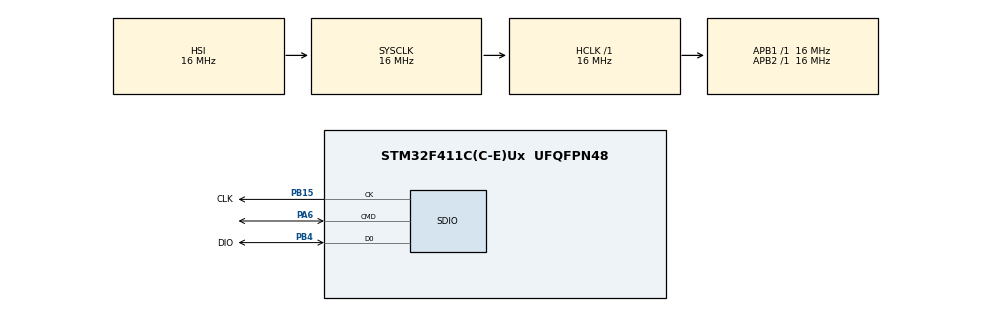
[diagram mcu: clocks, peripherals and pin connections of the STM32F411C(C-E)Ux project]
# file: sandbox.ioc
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Mcu.Family=STM32F4
Mcu.Name=STM32F411C(C-E)Ux
Mcu.Package=UFQFPN48
NVIC.PriorityGroup=NVIC_PRIORITYGROUP_4
PA6.Mode=SD_1_bit
PA6.Signal=SDIO_CMD
PB15.GPIO_Label=CLK
PB15.Mode=SD_1_bit
PB15.Signal=SDIO_CK
PB4.GPIO_Label=DIO
PB4.Mode=SD_1_bit
PB4.Signal=SDIO_D0
ProjectManager.HeapSize=0x200
ProjectManager.StackSize=0x400
ProjectManager.TargetToolchain=STM32CubeIDE
RCC.AHBFreq_Value=16000000
RCC.APB1Freq_Value=16000000
RCC.APB2Freq_Value=16000000
RCC.CortexFreq_Value=16000000
RCC.HSE_VALUE=25000000
RCC.HSI_VALUE=16000000
RCC.LSE_VALUE=32768
RCC.SYSCLKFreq_VALUE=16000000
RCC.VCOOutputFreq_Value=192000000
board=custom

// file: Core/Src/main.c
/* USER CODE BEGIN Header */
/**
  ******************************************************************************
  * @file           : main.c
  * @brief          : Main program body
  ******************************************************************************
  * @attention
  *
  * Copyright (c) 2023 STMicroelectronics.
  * All rights reserved.
  *
  * This software is licensed under terms that can be found in the LICENSE file
  * in the root directory of this software component.
  * If no LICENSE file comes with this software, it is provided AS-IS.
  *
  ******************************************************************************
  */
/* USER CODE END Header */
#include "main.h"
#include <TM1637Display.h>

SD_HandleTypeDef hsd;

void SystemClock_Config(void);
static void MX_GPIO_Init(void);
static void MX_SDIO_SD_Init(void);

int main(void)
{

  /* MCU Configuration--------------------------------------------------------*/

  /* Reset of all peripherals, Initializes the Flash interface and the Systick. */
  HAL_Init();

  /* Configure the system clock */
  SystemClock_Config();

  /* Initialize all configured peripherals */
  MX_GPIO_Init();
  MX_SDIO_SD_Init();
  /* USER CODE BEGIN 2 */
  // Create display object of type TM1637Display:
  TM1637Display display = TM1637Display(CLK_Pin, DIO_Pin);

  // Create array that turns all segments on:
  const uint8_t data[] = {0xff, 0xff, 0xff, 0xff};

  // Create array that turns all segments off:
  const uint8_t blank[] = {0x00, 0x00, 0x00, 0x00};

  // You can set the individual segments per digit to spell words or create other symbols:
  const uint8_t done[] = {
    SEG_B | SEG_C | SEG_D | SEG_E | SEG_G,           // d
    SEG_A | SEG_B | SEG_C | SEG_D | SEG_E | SEG_F,   // O
    SEG_C | SEG_E | SEG_G,                           // n
    SEG_A | SEG_D | SEG_E | SEG_F | SEG_G            // E
  };

  // Create degree Celsius symbol:
  const uint8_t celsius[] = {
    SEG_A | SEG_B | SEG_F | SEG_G,  // Circle
    SEG_A | SEG_D | SEG_E | SEG_F   // C
  };

  void setup() {
    // Clear the display:
    display.clear();
    delay(1000);
  }

  void loop() {
    // Set the brightness:
    display.setBrightness(7);
    // All segments on:
    display.setSegments(data);

    delay(1000);
    display.clear();
    delay(1000);

    // Show counter:
    int i;
    for (i = 0; i < 101; i++) {
      display.showNumberDec(i);
      delay(50);
    }

    delay(1000);
    display.clear();
    delay(1000);

    // Print number in different locations, loops 2 times:
    int j;
    for (j = 0; j < 2; j++) {
      for (i = 0; i < 4; i++) {
        display.showNumberDec(i, false, 1, i);
        delay(500);
        display.clear();
      }
    }

    delay(1000);
    display.clear();
    delay(1000);

    // Set brightness (0-7):
    int k;
    for (k = 0; k < 8; k++) {
      display.setBrightness(k);
      display.setSegments(data);
      delay(500);
    }

    delay(1000);
    display.clear();
    delay(1000);

    // Print 1234 with the center colon:
    display.showNumberDecEx(1234, 0b11100000, false, 4, 0);

    delay(1000);
    display.clear();
    delay(1000);

    int temperature = 24;
    display.showNumberDec(temperature, false, 2, 0);
    display.setSegments(celsius, 2, 2);

    delay(1000);
    display.clear();
    delay(1000);

    display.setSegments(done);
  /* USER CODE END 2 */

  /* Infinite loop */
  while (1)
  {

  }
}

void SystemClock_Config(void)
{
  RCC_OscInitTypeDef RCC_OscInitStruct = {0};
  RCC_ClkInitTypeDef RCC_ClkInitStruct = {0};

  /** Configure the main internal regulator output voltage
  */
  __HAL_RCC_PWR_CLK_ENABLE();
  __HAL_PWR_VOLTAGESCALING_CONFIG(PWR_REGULATOR_VOLTAGE_SCALE1);

  /** Initializes the RCC Oscillators according to the specified parameters
  * in the RCC_OscInitTypeDef structure.
  */
  RCC_OscInitStruct.OscillatorType = RCC_OSCILLATORTYPE_HSI;
  RCC_OscInitStruct.HSIState = RCC_HSI_ON;
  RCC_OscInitStruct.HSICalibrationValue = RCC_HSICALIBRATION_DEFAULT;
  RCC_OscInitStruct.PLL.PLLState = RCC_PLL_ON;
  RCC_OscInitStruct.PLL.PLLSource = RCC_PLLSOURCE_HSI;
  RCC_OscInitStruct.PLL.PLLM = 16;
  RCC_OscInitStruct.PLL.PLLN = 192;
  RCC_OscInitStruct.PLL.PLLP = RCC_PLLP_DIV2;
  RCC_OscInitStruct.PLL.PLLQ = 4;
  if (HAL_RCC_OscConfig(&RCC_OscInitStruct) != HAL_OK)
  {
    Error_Handler();
  }

  /** Initializes the CPU, AHB and APB buses clocks
  */
  RCC_ClkInitStruct.ClockType = RCC_CLOCKTYPE_HCLK|RCC_CLOCKTYPE_SYSCLK
                              |RCC_CLOCKTYPE_PCLK1|RCC_CLOCKTYPE_PCLK2;
  RCC_ClkInitStruct.SYSCLKSource = RCC_SYSCLKSOURCE_HSI;
  RCC_ClkInitStruct.AHBCLKDivider = RCC_SYSCLK_DIV1;
  RCC_ClkInitStruct.APB1CLKDivider = RCC_HCLK_DIV1;
  RCC_ClkInitStruct.APB2CLKDivider = RCC_HCLK_DIV1;

  if (HAL_RCC_ClockConfig(&RCC_ClkInitStruct, FLASH_LATENCY_0) != HAL_OK)
  {
    Error_Handler();
  }
}

static void MX_SDIO_SD_Init(void)
{

  hsd.Instance = SDIO;
  hsd.Init.ClockEdge = SDIO_CLOCK_EDGE_RISING;
  hsd.Init.ClockBypass = SDIO_CLOCK_BYPASS_DISABLE;
  hsd.Init.ClockPowerSave = SDIO_CLOCK_POWER_SAVE_DISABLE;
  hsd.Init.BusWide = SDIO_BUS_WIDE_1B;
  hsd.Init.HardwareFlowControl = SDIO_HARDWARE_FLOW_CONTROL_DISABLE;
  hsd.Init.ClockDiv = 0;
  if (HAL_SD_Init(&hsd) != HAL_OK)
  {
    Error_Handler();
  }

}

static void MX_GPIO_Init(void)
{

  /* GPIO Ports Clock Enable */
  __HAL_RCC_GPIOA_CLK_ENABLE();
  __HAL_RCC_GPIOB_CLK_ENABLE();

}

void Error_Handler(void)
{
  __disable_irq();
  while (1)
  {
  }
}
